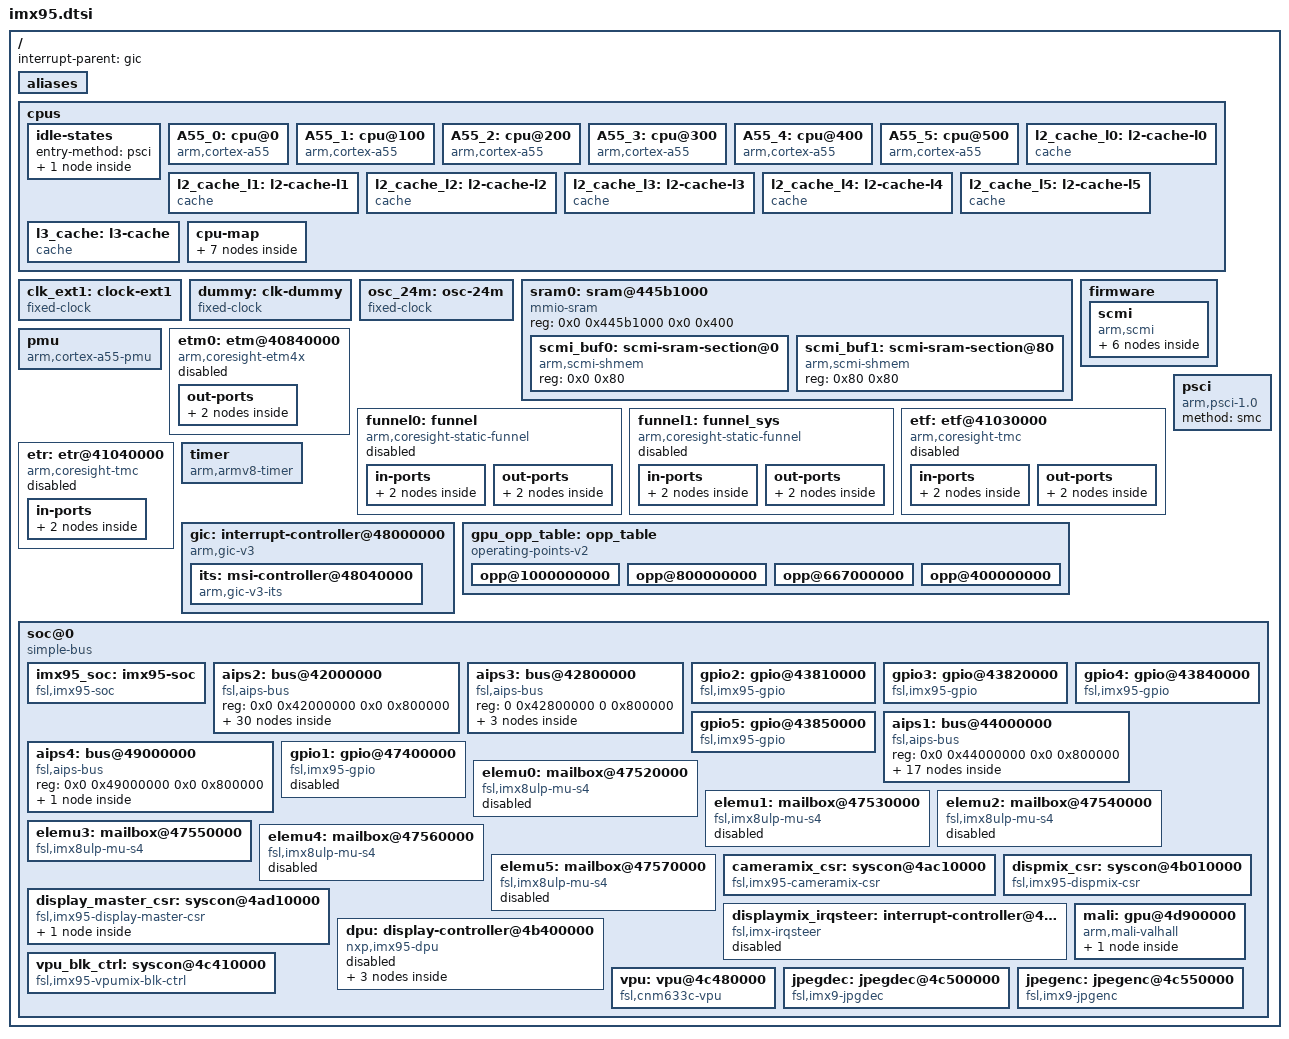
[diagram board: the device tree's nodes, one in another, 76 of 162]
// SPDX-License-Identifier: (GPL-2.0+ OR MIT)
/*
 * Copyright 2023 NXP
 */

#include <dt-bindings/clock/fsl,imx95-clock.h>
#include <dt-bindings/gpio/gpio.h>
#include <dt-bindings/input/input.h>
#include <dt-bindings/interrupt-controller/arm-gic.h>
#include <dt-bindings/power/fsl,imx95-power.h>

#include "imx95-pinfunc.h"

/ {
	interrupt-parent = <&gic>;
	#address-cells = <2>;
	#size-cells = <2>;

	aliases {
		gpio0 = &gpio1;
		gpio1 = &gpio2;
		gpio2 = &gpio3;
		gpio3 = &gpio4;
		gpio4 = &gpio5;
		i2c0 = &lpi2c1;
		i2c1 = &lpi2c2;
		i2c2 = &lpi2c3;
		i2c3 = &lpi2c4;
		i2c4 = &lpi2c5;
		i2c5 = &lpi2c6;
		i2c6 = &lpi2c7;
		i2c7 = &lpi2c8;
		mmc0 = &usdhc1;
		mmc1 = &usdhc2;
		mmc2 = &usdhc3;
		serial0 = &lpuart1;
		serial1 = &lpuart2;
		serial2 = &lpuart3;
		serial3 = &lpuart4;
		serial4 = &lpuart5;
		serial5 = &lpuart6;
		serial6 = &lpuart7;
		serial7 = &lpuart8;
	};

	cpus {
		#address-cells = <1>;
		#size-cells = <0>;

		idle-states {
			entry-method = "psci";

			cpu_pd_wait: cpu-pd-wait {
				compatible = "arm,idle-state";
				arm,psci-suspend-param = <0x0010033>;
				local-timer-stop;
				/*
				entry-latency-us = <10000>;
				exit-latency-us = <7000>;
				min-residency-us = <27000>;
				wakeup-latency-us = <15000>;
				*/
				entry-latency-us = <1000>;
				exit-latency-us = <700>;
				min-residency-us = <2700>;
				wakeup-latency-us = <1500>;
			};
		};

		A55_0: cpu@0 {
			device_type = "cpu";
			compatible = "arm,cortex-a55";
			reg = <0x0>;
			enable-method = "psci";
			#cooling-cells = <2>;
			cpu-idle-states = <&cpu_pd_wait>;
			power-domains = <&scmi_devpd IMX95_PERF_A55>;
			power-domain-names = "perf";
			i-cache-size = <32768>;
			i-cache-line-size = <64>;
			i-cache-sets = <128>;
			d-cache-size = <32768>;
			d-cache-line-size = <64>;
			d-cache-sets = <128>;
			next-level-cache = <&l2_cache_l0>;
		};

		A55_1: cpu@100 {
			device_type = "cpu";
			compatible = "arm,cortex-a55";
			reg = <0x100>;
			enable-method = "psci";
			#cooling-cells = <2>;
			cpu-idle-states = <&cpu_pd_wait>;
			power-domains = <&scmi_devpd IMX95_PERF_A55>;
			power-domain-names = "perf";
			i-cache-size = <32768>;
			i-cache-line-size = <64>;
			i-cache-sets = <128>;
			d-cache-size = <32768>;
			d-cache-line-size = <64>;
			d-cache-sets = <128>;
			next-level-cache = <&l2_cache_l1>;
		};

		A55_2: cpu@200 {
			device_type = "cpu";
			compatible = "arm,cortex-a55";
			reg = <0x200>;
			enable-method = "psci";
			#cooling-cells = <2>;
			cpu-idle-states = <&cpu_pd_wait>;
			power-domains = <&scmi_devpd IMX95_PERF_A55>;
			power-domain-names = "perf";
			i-cache-size = <32768>;
			i-cache-line-size = <64>;
			i-cache-sets = <128>;
			d-cache-size = <32768>;
			d-cache-line-size = <64>;
			d-cache-sets = <128>;
			next-level-cache = <&l2_cache_l2>;
		};

		A55_3: cpu@300 {
			device_type = "cpu";
			compatible = "arm,cortex-a55";
			reg = <0x300>;
			enable-method = "psci";
			#cooling-cells = <2>;
			power-domains = <&scmi_devpd IMX95_PERF_A55>;
			power-domain-names = "perf";
			i-cache-size = <32768>;
			i-cache-line-size = <64>;
			i-cache-sets = <128>;
			d-cache-size = <32768>;
			d-cache-line-size = <64>;
			d-cache-sets = <128>;
			next-level-cache = <&l2_cache_l3>;
		};

		A55_4: cpu@400 {
			device_type = "cpu";
			compatible = "arm,cortex-a55";
			reg = <0x400>;
			power-domains = <&scmi_devpd IMX95_PERF_A55>;
			power-domain-names = "perf";
			enable-method = "psci";
			#cooling-cells = <2>;
			cpu-idle-states = <&cpu_pd_wait>;
			i-cache-size = <32768>;
			i-cache-line-size = <64>;
			i-cache-sets = <128>;
			d-cache-size = <32768>;
			d-cache-line-size = <64>;
			d-cache-sets = <128>;
			next-level-cache = <&l2_cache_l4>;
		};

		A55_5: cpu@500 {
			device_type = "cpu";
			compatible = "arm,cortex-a55";
			reg = <0x500>;
			power-domains = <&scmi_devpd IMX95_PERF_A55>;
			power-domain-names = "perf";
			enable-method = "psci";
			#cooling-cells = <2>;
			cpu-idle-states = <&cpu_pd_wait>;
			i-cache-size = <32768>;
			i-cache-line-size = <64>;
			i-cache-sets = <128>;
			d-cache-size = <32768>;
			d-cache-line-size = <64>;
			d-cache-sets = <128>;
			next-level-cache = <&l2_cache_l5>;
		};

		l2_cache_l0: l2-cache-l0 {
			compatible = "cache";
			cache-size = <65536>;
			cache-line-size = <64>;
			cache-sets = <256>;
			cache-level = <2>;
			cache-unified;
			next-level-cache = <&l3_cache>;
		};

		l2_cache_l1: l2-cache-l1 {
			compatible = "cache";
			cache-size = <65536>;
			cache-line-size = <64>;
			cache-sets = <256>;
			cache-level = <2>;
			cache-unified;
			next-level-cache = <&l3_cache>;
		};

		l2_cache_l2: l2-cache-l2 {
			compatible = "cache";
			cache-size = <65536>;
			cache-line-size = <64>;
			cache-sets = <256>;
			cache-level = <2>;
			cache-unified;
			next-level-cache = <&l3_cache>;
		};

		l2_cache_l3: l2-cache-l3 {
			compatible = "cache";
			cache-size = <65536>;
			cache-line-size = <64>;
			cache-sets = <256>;
			cache-level = <2>;
			cache-unified;
			next-level-cache = <&l3_cache>;
		};

		l2_cache_l4: l2-cache-l4 {
			compatible = "cache";
			cache-size = <65536>;
			cache-line-size = <64>;
			cache-sets = <256>;
			cache-level = <2>;
			cache-unified;
			next-level-cache = <&l3_cache>;
		};

		l2_cache_l5: l2-cache-l5 {
			compatible = "cache";
			cache-size = <65536>;
			cache-line-size = <64>;
			cache-sets = <256>;
			cache-level = <2>;
			cache-unified;
			next-level-cache = <&l3_cache>;
		};

		l3_cache: l3-cache {
			compatible = "cache";
			cache-size = <524288>;
			cache-line-size = <64>;
			cache-sets = <1024>;
			cache-level = <3>;
			cache-unified;
		};

		cpu-map {
			cluster0 {
				core0 {
					cpu = <&A55_0>;
				};

				core1 {
					cpu = <&A55_1>;
				};

				core2 {
					cpu = <&A55_2>;
				};

				core3 {
					cpu = <&A55_3>;
				};

				core4 {
					cpu = <&A55_4>;
				};

				core5 {
					cpu = <&A55_5>;
				};
			};
		};
	};

	clk_ext1: clock-ext1 {
		compatible = "fixed-clock";
		#clock-cells = <0>;
		clock-frequency = <133000000>;
		clock-output-names = "clk_ext1";
	};

	dummy: clk-dummy {
		compatible = "fixed-clock";
		#clock-cells = <0>;
		clock-frequency = <0>;
		clock-output-names = "dummy";
	};

	osc_24m: osc-24m {
		compatible = "fixed-clock";
		#clock-cells = <0>;
		clock-frequency = <24000000>;
		clock-output-names = "osc_24m";
	};

	sram0: sram@445b1000 {
		compatible = "mmio-sram";
		reg = <0x0 0x445b1000 0x0 0x400>;

		#address-cells = <1>;
		#size-cells = <1>;
		ranges = <0x0 0x0 0x445b1000 0x400>;

		scmi_buf0: scmi-sram-section@0 {
			compatible = "arm,scmi-shmem";
			reg = <0x0 0x80>;
		};

		scmi_buf1: scmi-sram-section@80 {
			compatible = "arm,scmi-shmem";
			reg = <0x80 0x80>;
		};
	};

	firmware {
		scmi {
			compatible = "arm,scmi";
			mboxes = <&mu2 5 0>, <&mu2 3 0>, <&mu2 3 1>;
			shmem = <&scmi_buf0>, <&scmi_buf1>;
			#address-cells = <1>;
			#size-cells = <0>;

			scmi_devpd: protocol@11 {
				reg = <0x11>;
				#power-domain-cells = <1>;
			};

			scmi_sys_power: protocol@12 {
				reg = <0x12>;
			};

			scmi_perf: protocol@13 {
				reg = <0x13>;
				#clock-cells = <1>;
				#power-domain-cells = <1>;
			};

			scmi_clk: protocol@14 {
				reg = <0x14>;
				#clock-cells = <1>;
			};

			scmi_iomuxc: protocol@19 {
				reg = <0x19>;
			};

			scmi_bbm: protocol@81 {
				reg = <0x81>;
			};
		};
	};

	pmu {
		compatible = "arm,cortex-a55-pmu";
		interrupts = <GIC_PPI 7 (GIC_CPU_MASK_SIMPLE(6) | IRQ_TYPE_LEVEL_HIGH)>;
	};

	etm0: etm@40840000 {
		compatible = "arm,coresight-etm4x", "arm,primecell";
		reg = <0x0 0x40840000 0x0 0x10000>;
		arm,primecell-periphid = <0xbb95d>;
		cpu = <&A55_0>;
		clocks = <&scmi_clk IMX95_CLK_A55PERIPH>;
		clock-names = "apb_pclk";
		status = "disabled";

		out-ports {
			port {
				etm0_out_port: endpoint {
					remote-endpoint = <&ca_funnel_in_port0>;
				};
			};
		};
	};

	funnel0: funnel {
		/*
		 * non-configurable funnel don't show up on the AMBA
		 * bus.  As such no need to add "arm,primecell".
		 */
		compatible = "arm,coresight-static-funnel";
		status = "disabled";

		in-ports {
			#address-cells = <1>;
			#size-cells = <0>;

			port@0 {
				reg = <0>;
				ca_funnel_in_port0: endpoint {
					remote-endpoint = <&etm0_out_port>;
				};
			};
		};

		out-ports {
			port {
				ca_funnel_out_port0: endpoint {
					remote-endpoint = <&hugo_funnel_in_port0>;
				};
			};
		};
	};

	funnel1: funnel_sys {
		compatible = "arm,coresight-static-funnel";
		status = "disabled";

		in-ports {
			#address-cells = <1>;
			#size-cells = <0>;

			port@0 {
				reg = <0>;
				hugo_funnel_in_port0: endpoint {
					remote-endpoint = <&ca_funnel_out_port0>;
				};
			};
		};

		out-ports {
			port {
				hugo_funnel_out_port0: endpoint {
					remote-endpoint = <&etf_in_port>;
				};
			};
		};
	};

	etf: etf@41030000 {
		compatible = "arm,coresight-tmc", "arm,primecell";
		reg = <0x0 0x41030000 0x0 0x1000>;
		clocks = <&scmi_clk IMX95_CLK_A55PERIPH>;
		clock-names = "apb_pclk";
		status = "disabled";

		in-ports {
			port {
				etf_in_port: endpoint {
					remote-endpoint = <&hugo_funnel_out_port0>;
				};
			};
		};

		out-ports {
			port {
				etf_out_port: endpoint {
					remote-endpoint = <&etr_in_port>;
				};
			};
		};
	};

	etr: etr@41040000 {
		compatible = "arm,coresight-tmc", "arm,primecell";
		reg = <0x0 0x41040000 0x0 0x1000>;
		clocks = <&scmi_clk IMX95_CLK_A55PERIPH>;
		clock-names = "apb_pclk";
		status = "disabled";

		in-ports {
			port {
				etr_in_port: endpoint {
					remote-endpoint = <&etf_out_port>;
				};
			};
		};
	};

	psci {
		compatible = "arm,psci-1.0";
		method = "smc";
	};

	timer {
		compatible = "arm,armv8-timer";
		interrupts = <GIC_PPI 13 (GIC_CPU_MASK_SIMPLE(6) | IRQ_TYPE_LEVEL_LOW)>,
			     <GIC_PPI 14 (GIC_CPU_MASK_SIMPLE(6) | IRQ_TYPE_LEVEL_LOW)>,
			     <GIC_PPI 11 (GIC_CPU_MASK_SIMPLE(6) | IRQ_TYPE_LEVEL_LOW)>,
			     <GIC_PPI 10 (GIC_CPU_MASK_SIMPLE(6) | IRQ_TYPE_LEVEL_LOW)>;
		clock-frequency = <24000000>;
		arm,no-tick-in-suspend;
		interrupt-parent = <&gic>;
	};

	gic: interrupt-controller@48000000 {
		compatible = "arm,gic-v3";
		#address-cells = <2>;
		#size-cells = <2>;
		reg = <0 0x48000000 0 0x10000>,
		      <0 0x48060000 0 0xc0000>;
		#interrupt-cells = <3>;
		interrupt-controller;
		interrupts = <GIC_PPI 9 IRQ_TYPE_LEVEL_HIGH>;
		interrupt-parent = <&gic>;
		dma-noncoherent;

		ranges;

		its: msi-controller@48040000 {
			compatible = "arm,gic-v3-its";
			dma-noncoherent;
			msi-controller;
			reg = <0 0x48040000 0 0x20000>;
		};
	};


	gpu_opp_table: opp_table {
		compatible = "operating-points-v2", "operating-points-v2-mali";

		opp@1000000000 {
			opp-hz = /bits/ 64 <1000000000>;
			opp-hz-real = /bits/ 64 <1000000000>, /bits/ 64 <500000000>;
		};

		opp@800000000 {
			opp-hz = /bits/ 64 <800000000>;
			opp-hz-real = /bits/ 64 <800000000>, /bits/ 64 <500000000>;
		};

		opp@667000000 {
			opp-hz = /bits/ 64 <667000000>;
			opp-hz-real = /bits/ 64 <667000000>, /bits/ 64 <400000000>;
		};

		opp@400000000 {
			opp-hz = /bits/ 64 <400000000>;
			opp-hz-real = /bits/ 64 <400000000>, /bits/ 64 <250000000>;
		};
	};

	soc@0 {
		compatible = "simple-bus";
		#address-cells = <2>;
		#size-cells = <2>;
		ranges = <0x0 0x0 0x0 0x0 0x0 0x80000000>,
			 <0x0 0x28000000 0x0 0x28000000 0x0 0x10000000>;

		imx95_soc: imx95-soc {
			compatible = "fsl,imx95-soc";
		};

		aips2: bus@42000000 {
			compatible = "fsl,aips-bus", "simple-bus";
			reg = <0x0 0x42000000 0x0 0x800000>;
			#address-cells = <1>;
			#size-cells = <1>;
			ranges = <0x42000000 0x0 0x42000000 0x8000000>;

			mu7: mailbox@42430000 {
				compatible = "fsl,imx95-mu", "fsl,imx8ulp-mu";
				reg = <0x42430000 0x10000>;
				interrupts = <GIC_SPI 234 IRQ_TYPE_LEVEL_HIGH>;
				clocks = <&scmi_clk IMX95_CLK_BUSWAKEUP>;
				#mbox-cells = <2>;
				status = "disabled";
			};

			flexcan2: can@425b0000 {
				compatible = "fsl,imx95-flexcan", "fsl,imx93-flexcan";
				reg = <0x425b0000 0x10000>;
				interrupts = <GIC_SPI 38 IRQ_TYPE_LEVEL_HIGH>;
				clocks = <&scmi_clk IMX95_CLK_BUSWAKEUP>,
					 <&scmi_clk IMX95_CLK_CAN2>;
				clock-names = "ipg", "per";
				assigned-clocks = <&scmi_clk IMX95_CLK_CAN2>;
				assigned-clock-parents = <&scmi_clk IMX95_CLK_SYSPLL1_PFD1_DIV2>;
				assigned-clock-rates = <40000000>;
				fsl,clk-source = /bits/ 8 <0>;
				status = "disabled";
			};

			flexcan3: can@42600000 {
				compatible = "fsl,imx95-flexcan", "fsl,imx93-flexcan";
				reg = <0x42600000 0x10000>;
				interrupts = <GIC_SPI 40 IRQ_TYPE_LEVEL_HIGH>;
				clocks = <&scmi_clk IMX95_CLK_BUSWAKEUP>,
					 <&scmi_clk IMX95_CLK_CAN3>;
				clock-names = "ipg", "per";
				assigned-clocks = <&scmi_clk IMX95_CLK_CAN3>;
				assigned-clock-parents = <&scmi_clk IMX95_CLK_SYSPLL1_PFD1_DIV2>;
				assigned-clock-rates = <40000000>;
				fsl,clk-source = /bits/ 8 <0>;
				status = "disabled";
			};

			mu8: mailbox@42730000 {
				compatible = "fsl,imx95-mu", "fsl,imx8ulp-mu";
				reg = <0x42730000 0x10000>;
				interrupts = <GIC_SPI 235 IRQ_TYPE_LEVEL_HIGH>;
				clocks = <&scmi_clk IMX95_CLK_BUSWAKEUP>;
				#mbox-cells = <2>;
				status = "disabled";
			};

			tpm3: pwm@424e0000 {
				compatible = "fsl,imx7ulp-pwm";
				reg = <0x424e0000 0x1000>;
				clocks = <&scmi_clk IMX95_CLK_BUSWAKEUP>;
				#pwm-cells = <3>;
				status = "disabled";
			};

			tpm4: pwm@424f0000 {
				compatible = "fsl,imx7ulp-pwm";
				reg = <0x424f0000 0x1000>;
				clocks = <&scmi_clk IMX95_CLK_TPM4>;
				#pwm-cells = <3>;
				status = "disabled";
			};

			tpm5: pwm@42500000 {
				compatible = "fsl,imx7ulp-pwm";
				reg = <0x42500000 0x1000>;
				clocks = <&scmi_clk IMX95_CLK_TPM5>;
				#pwm-cells = <3>;
				status = "disabled";
			};

			tpm6: pwm@42510000 {
				compatible = "fsl,imx7ulp-pwm";
				reg = <0x42510000 0x1000>;
				clocks = <&scmi_clk IMX95_CLK_TPM6>;
				#pwm-cells = <3>;
				status = "disabled";
			};

			lpi2c3: i2c@42530000 {
				compatible = "fsl,imx95-lpi2c", "fsl,imx7ulp-lpi2c";
				reg = <0x42530000 0x10000>;
				interrupts = <GIC_SPI 58 IRQ_TYPE_LEVEL_HIGH>;
				clocks = <&scmi_clk IMX95_CLK_LPI2C3>,
					 <&scmi_clk IMX95_CLK_BUSWAKEUP>;
				clock-names = "per", "ipg";
				status = "disabled";
			};

			lpi2c4: i2c@42540000 {
				compatible = "fsl,imx95-lpi2c", "fsl,imx7ulp-lpi2c";
				reg = <0x42540000 0x10000>;
				interrupts = <GIC_SPI 59 IRQ_TYPE_LEVEL_HIGH>;
				clocks = <&scmi_clk IMX95_CLK_LPI2C4>,
					 <&scmi_clk IMX95_CLK_BUSWAKEUP>;
				clock-names = "per", "ipg";
				status = "disabled";
			};

			lpspi3: spi@42550000 {
				#address-cells = <1>;
				#size-cells = <0>;
				compatible = "fsl,imx95-spi", "fsl,imx7ulp-spi";
				reg = <0x42550000 0x10000>;
				interrupts = <GIC_SPI 61 IRQ_TYPE_LEVEL_HIGH>;
				clocks = <&scmi_clk IMX95_CLK_LPSPI3>,
					 <&scmi_clk IMX95_CLK_BUSWAKEUP>;
				clock-names = "per", "ipg";
				status = "disabled";
			};

			lpspi4: spi@42560000 {
				#address-cells = <1>;
				#size-cells = <0>;
				compatible = "fsl,imx95-spi", "fsl,imx7ulp-spi";
				reg = <0x42560000 0x10000>;
				interrupts = <GIC_SPI 62 IRQ_TYPE_LEVEL_HIGH>;
				clocks = <&scmi_clk IMX95_CLK_LPSPI4>,
					 <&scmi_clk IMX95_CLK_BUSWAKEUP>;
				clock-names = "per", "ipg";
				status = "disabled";
			};

			lpuart3: serial@42570000 {
				compatible = "fsl,imx95-lpuart", "fsl,imx8ulp-lpuart",
					     "fsl,imx7ulp-lpuart";
				reg = <0x42570000 0x1000>;
				interrupts = <GIC_SPI 64 IRQ_TYPE_LEVEL_HIGH>;
				clocks = <&scmi_clk IMX95_CLK_LPUART3>;
				clock-names = "ipg";
				status = "disabled";
			};

			lpuart4: serial@42580000 {
				compatible = "fsl,imx95-lpuart", "fsl,imx8ulp-lpuart",
					     "fsl,imx7ulp-lpuart";
				reg = <0x42580000 0x1000>;
				interrupts = <GIC_SPI 65 IRQ_TYPE_LEVEL_HIGH>;
				clocks = <&scmi_clk IMX95_CLK_LPUART4>;
				clock-names = "ipg";
				status = "disabled";
			};

			lpuart5: serial@42590000 {
				compatible = "fsl,imx95-lpuart", "fsl,imx8ulp-lpuart",
					     "fsl,imx7ulp-lpuart";
				reg = <0x42590000 0x1000>;
				interrupts = <GIC_SPI 66 IRQ_TYPE_LEVEL_HIGH>;
				clocks = <&scmi_clk IMX95_CLK_LPUART5>;
				clock-names = "ipg";
				status = "disabled";
			};

			lpuart6: serial@425a0000 {
				compatible = "fsl,imx95-lpuart", "fsl,imx8ulp-lpuart",
					     "fsl,imx7ulp-lpuart";
				reg = <0x425a0000 0x1000>;
				interrupts = <GIC_SPI 67 IRQ_TYPE_LEVEL_HIGH>;
				clocks = <&scmi_clk IMX95_CLK_LPUART6>;
				clock-names = "ipg";
				status = "disabled";
			};

			flexio_i2c_master: flexio@425c0000 {
				compatible = "imx,flexio_i2c_master";
				reg = <0x425c0000 0x10000>;
				interrupts = <GIC_SPI 46 IRQ_TYPE_LEVEL_HIGH>;
				clocks = <&scmi_clk IMX95_CLK_BUSWAKEUP>,
					 <&scmi_clk IMX95_CLK_BUSWAKEUP>;
				clock-names = "per", "ipg";
				assigned-clocks = <&scmi_clk IMX95_CLK_BUSWAKEUP>;
				assigned-clock-parents = <&scmi_clk IMX95_CLK_BUSWAKEUP>;
				assigned-clock-rates = <24000000>;
				status = "disabled";
			};

			flexspi1: spi@425e0000 {
				#address-cells = <1>;
				#size-cells = <0>;
				compatible = "nxp,imx95-fspi", "nxp,imx8mm-fspi";
				reg = <0x425e0000 0x10000>, <0x28000000 0x8000000>;
				reg-names = "fspi_base", "fspi_mmap";
				interrupts = <GIC_SPI 48 IRQ_TYPE_LEVEL_HIGH>;
				clocks = <&scmi_clk IMX95_CLK_FLEXSPI1>,
					 <&scmi_clk IMX95_CLK_FLEXSPI1>;
				clock-names = "fspi", "fspi_en";
				assigned-clocks = <&scmi_clk IMX95_CLK_FLEXSPI1>;
				assigned-clock-parents = <&scmi_clk IMX95_CLK_SYSPLL1_PFD1>;
				assigned-clock-rates = <200000000>;
				status = "disabled";
			};

			lpuart7: serial@42690000 {
				compatible = "fsl,imx95-lpuart", "fsl,imx8ulp-lpuart",
					     "fsl,imx7ulp-lpuart";
				reg = <0x42690000 0x1000>;
				interrupts = <GIC_SPI 68 IRQ_TYPE_LEVEL_HIGH>;
				clocks = <&scmi_clk IMX95_CLK_LPUART7>;
				clock-names = "ipg";
				status = "disabled";
			};

			lpuart8: serial@426a0000 {
				compatible = "fsl,imx95-lpuart", "fsl,imx8ulp-lpuart",
					     "fsl,imx7ulp-lpuart";
				reg = <0x426a0000 0x1000>;
				interrupts = <GIC_SPI 69 IRQ_TYPE_LEVEL_HIGH>;
				clocks = <&scmi_clk IMX95_CLK_LPUART8>;
				clock-names = "ipg";
				status = "disabled";
			};

			lpi2c5: i2c@426b0000 {
				compatible = "fsl,imx95-lpi2c", "fsl,imx7ulp-lpi2c";
				reg = <0x426b0000 0x10000>;
				interrupts = <GIC_SPI 181 IRQ_TYPE_LEVEL_HIGH>;
				clocks = <&scmi_clk IMX95_CLK_LPI2C5>,
					 <&scmi_clk IMX95_CLK_BUSWAKEUP>;
				clock-names = "per", "ipg";
				status = "disabled";
			};

			lpi2c6: i2c@426c0000 {
				compatible = "fsl,imx95-lpi2c", "fsl,imx7ulp-lpi2c";
				reg = <0x426c0000 0x10000>;
				interrupts = <GIC_SPI 182 IRQ_TYPE_LEVEL_HIGH>;
				clocks = <&scmi_clk IMX95_CLK_LPI2C6>,
					 <&scmi_clk IMX95_CLK_BUSWAKEUP>;
				clock-names = "per", "ipg";
				status = "disabled";
			};

			lpi2c7: i2c@426d0000 {
				compatible = "fsl,imx95-lpi2c", "fsl,imx7ulp-lpi2c";
				reg = <0x426d0000 0x10000>;
				interrupts = <GIC_SPI 183 IRQ_TYPE_LEVEL_HIGH>;
				clocks = <&scmi_clk IMX95_CLK_LPI2C7>,
					 <&scmi_clk IMX95_CLK_BUSWAKEUP>;
				clock-names = "per", "ipg";
				status = "disabled";
			};

			lpi2c8: i2c@426e0000 {
				compatible = "fsl,imx95-lpi2c", "fsl,imx7ulp-lpi2c";
				reg = <0x426e0000 0x10000>;
				interrupts = <GIC_SPI 184 IRQ_TYPE_LEVEL_HIGH>;
				clocks = <&scmi_clk IMX95_CLK_LPI2C8>,
					 <&scmi_clk IMX95_CLK_BUSWAKEUP>;
				clock-names = "per", "ipg";
				status = "disabled";
			};

			lpspi5: spi@426f0000 {
				#address-cells = <1>;
				#size-cells = <0>;
				compatible = "fsl,imx95-spi", "fsl,imx7ulp-spi";
				reg = <0x426f0000 0x10000>;
				interrupts = <GIC_SPI 177 IRQ_TYPE_LEVEL_HIGH>;
				clocks = <&scmi_clk IMX95_CLK_LPSPI5>,
					 <&scmi_clk IMX95_CLK_BUSWAKEUP>;
				clock-names = "per", "ipg";
				status = "disabled";
			};

			lpspi6: spi@42700000 {
				#address-cells = <1>;
				#size-cells = <0>;
				compatible = "fsl,imx95-spi", "fsl,imx7ulp-spi";
				reg = <0x42700000 0x10000>;
				interrupts = <GIC_SPI 178 IRQ_TYPE_LEVEL_HIGH>;
				clocks = <&scmi_clk IMX95_CLK_LPSPI6>,
					 <&scmi_clk IMX95_CLK_BUSWAKEUP>;
				clock-names = "per", "ipg";
				status = "disabled";
			};

			lpspi7: spi@42710000 {
				#address-cells = <1>;
				#size-cells = <0>;
				compatible = "fsl,imx95-spi", "fsl,imx7ulp-spi";
				reg = <0x42710000 0x10000>;
				interrupts = <GIC_SPI 179 IRQ_TYPE_LEVEL_HIGH>;
				clocks = <&scmi_clk IMX95_CLK_LPSPI7>,
					 <&scmi_clk IMX95_CLK_BUSWAKEUP>;
				clock-names = "per", "ipg";
				status = "disabled";
			};

			lpspi8: spi@42720000 {
				#address-cells = <1>;
				#size-cells = <0>;
				compatible = "fsl,imx95-spi", "fsl,imx7ulp-spi";
				reg = <0x42720000 0x10000>;
				interrupts = <GIC_SPI 180 IRQ_TYPE_LEVEL_HIGH>;
				clocks = <&scmi_clk IMX95_CLK_LPSPI8>,
					 <&scmi_clk IMX95_CLK_BUSWAKEUP>;
				clock-names = "per", "ipg";
				status = "disabled";
			};

			flexcan4: can@427c0000 {
				compatible = "fsl,imx95-flexcan", "fsl,imx93-flexcan";
				reg = <0x427c0000 0x10000>;
				interrupts = <GIC_SPI 42 IRQ_TYPE_LEVEL_HIGH>;
				clocks = <&scmi_clk IMX95_CLK_BUSWAKEUP>,
					 <&scmi_clk IMX95_CLK_CAN4>;
				clock-names = "ipg", "per";
				assigned-clocks = <&scmi_clk IMX95_CLK_CAN4>;
				assigned-clock-parents = <&scmi_clk IMX95_CLK_SYSPLL1_PFD1_DIV2>;
				assigned-clock-rates = <40000000>;
				fsl,clk-source = /bits/ 8 <0>;
				status = "disabled";
			};

			flexcan5: can@427d0000 {
				compatible = "fsl,imx95-flexcan", "fsl,imx93-flexcan";
				reg = <0x427d0000 0x10000>;
				interrupts = <GIC_SPI 44 IRQ_TYPE_LEVEL_HIGH>;
				clocks = <&scmi_clk IMX95_CLK_BUSWAKEUP>,
					 <&scmi_clk IMX95_CLK_CAN5>;
				clock-names = "ipg", "per";
				assigned-clocks = <&scmi_clk IMX95_CLK_CAN5>;
				assigned-clock-parents = <&scmi_clk IMX95_CLK_SYSPLL1_PFD1_DIV2>;
				assigned-clock-rates = <40000000>;
				fsl,clk-source = /bits/ 8 <0>;
				status = "disabled";
			};
		};

		aips3: bus@42800000 {
			compatible = "fsl,aips-bus", "simple-bus";
			reg = <0 0x42800000 0 0x800000>;
			#address-cells = <1>;
			#size-cells = <1>;
			ranges = <0x42800000 0x0 0x42800000 0x800000>;

			usdhc1: mmc@42850000 {
				compatible = "fsl,imx95-usdhc", "fsl,imx8mm-usdhc";
				reg = <0x42850000 0x10000>;
				interrupts = <GIC_SPI 86 IRQ_TYPE_LEVEL_HIGH>;
				clocks = <&scmi_clk IMX95_CLK_BUSWAKEUP>,
					 <&scmi_clk IMX95_CLK_WAKEUPAXI>,
					 <&scmi_clk IMX95_CLK_USDHC1>;
				clock-names = "ipg", "ahb", "per";
				assigned-clocks = <&scmi_clk IMX95_CLK_USDHC1>;
				assigned-clock-parents = <&scmi_clk IMX95_CLK_SYSPLL1_PFD1>;
				assigned-clock-rates = <400000000>;
				bus-width = <8>;
				fsl,tuning-start-tap = <1>;
				fsl,tuning-step= <2>;
				status = "disabled";
			};

			usdhc2: mmc@42860000 {
				compatible = "fsl,imx95-usdhc", "fsl,imx8mm-usdhc";
				reg = <0x42860000 0x10000>;
				interrupts = <GIC_SPI 87 IRQ_TYPE_LEVEL_HIGH>;
				clocks = <&scmi_clk IMX95_CLK_BUSWAKEUP>,
					 <&scmi_clk IMX95_CLK_WAKEUPAXI>,
					 <&scmi_clk IMX95_CLK_USDHC2>;
				clock-names = "ipg", "ahb", "per";
				assigned-clocks = <&scmi_clk IMX95_CLK_USDHC2>;
				assigned-clock-parents = <&scmi_clk IMX95_CLK_SYSPLL1_PFD1>;
				assigned-clock-rates = <200000000>;
				bus-width = <4>;
				fsl,tuning-start-tap = <1>;
				fsl,tuning-step= <2>;
				status = "disabled";
			};

			usdhc3: mmc@428b0000 {
				compatible = "fsl,imx95-usdhc", "fsl,imx8mm-usdhc";
				reg = <0x428b0000 0x10000>;
				interrupts = <GIC_SPI 191 IRQ_TYPE_LEVEL_HIGH>;
				clocks = <&scmi_clk IMX95_CLK_BUSWAKEUP>,
					 <&scmi_clk IMX95_CLK_WAKEUPAXI>,
					 <&scmi_clk IMX95_CLK_USDHC3>;
				clock-names = "ipg", "ahb", "per";
				bus-width = <4>;
				fsl,tuning-start-tap = <1>;
				fsl,tuning-step= <2>;
				status = "disabled";
			};
		};

		gpio2: gpio@43810000 {
			compatible = "fsl,imx95-gpio", "fsl,imx8ulp-gpio";
			reg = <0x0 0x43810000 0x0 0x1000>;
			gpio-controller;
			#gpio-cells = <2>;
			interrupts = <GIC_SPI 49 IRQ_TYPE_LEVEL_HIGH>,
				     <GIC_SPI 50 IRQ_TYPE_LEVEL_HIGH>;
			interrupt-controller;
			#interrupt-cells = <2>;
			clocks = <&scmi_clk IMX95_CLK_BUSWAKEUP>,
				 <&scmi_clk IMX95_CLK_BUSWAKEUP>;
			clock-names = "gpio", "port";
			gpio-ranges = <&scmi_iomuxc 0 4 32>;
		};

		gpio3: gpio@43820000 {
			compatible = "fsl,imx95-gpio", "fsl,imx8ulp-gpio";
			reg = <0x0 0x43820000 0x0 0x1000>;
			gpio-controller;
			#gpio-cells = <2>;
			interrupts = <GIC_SPI 51 IRQ_TYPE_LEVEL_HIGH>,
				     <GIC_SPI 52 IRQ_TYPE_LEVEL_HIGH>;
			interrupt-controller;
			#interrupt-cells = <2>;
			clocks = <&scmi_clk IMX95_CLK_BUSWAKEUP>,
				 <&scmi_clk IMX95_CLK_BUSWAKEUP>;
			clock-names = "gpio", "port";
			gpio-ranges = <&scmi_iomuxc 0 104 8>, <&scmi_iomuxc 8 74 18>,
				      <&scmi_iomuxc 26 42 2>, <&scmi_iomuxc 28 0 4>;
		};

		gpio4: gpio@43840000 {
			compatible = "fsl,imx95-gpio", "fsl,imx8ulp-gpio";
			reg = <0x0 0x43840000 0x0 0x1000>;
			gpio-controller;
			#gpio-cells = <2>;
			interrupts = <GIC_SPI 53 IRQ_TYPE_LEVEL_HIGH>,
				     <GIC_SPI 54 IRQ_TYPE_LEVEL_HIGH>;
			interrupt-controller;
			#interrupt-cells = <2>;
			clocks = <&scmi_clk IMX95_CLK_BUSWAKEUP>,
				 <&scmi_clk IMX95_CLK_BUSWAKEUP>;
			clock-names = "gpio", "port";
			gpio-ranges = <&scmi_iomuxc 0 46 28>, <&scmi_iomuxc 28 44 2>;
		};

		gpio5: gpio@43850000 {
			compatible = "fsl,imx95-gpio", "fsl,imx8ulp-gpio";
			reg = <0x0 0x43850000 0x0 0x1000>;
			gpio-controller;
			#gpio-cells = <2>;
			interrupts = <GIC_SPI 55 IRQ_TYPE_LEVEL_HIGH>,
				     <GIC_SPI 56 IRQ_TYPE_LEVEL_HIGH>;
			interrupt-controller;
			#interrupt-cells = <2>;
			clocks = <&scmi_clk IMX95_CLK_BUSWAKEUP>,
				 <&scmi_clk IMX95_CLK_BUSWAKEUP>;
			clock-names = "gpio", "port";
			gpio-ranges = <&scmi_iomuxc 0 92 12>, <&scmi_iomuxc 12 36 6>;
		};

		aips1: bus@44000000 {
			compatible = "fsl,aips-bus", "simple-bus";
			reg = <0x0 0x44000000 0x0 0x800000>;
			#address-cells = <1>;
			#size-cells = <1>;
			ranges = <0x44000000 0x0 0x44000000 0x800000>;

			edma1: dma-controller@44000000 {
				compatible = "fsl,imx93-edma";
				reg = <0x44000000 0x10000>,
				      <0x44010000 0x10000>, <0x44020000 0x10000>,
				      <0x44030000 0x10000>, <0x44040000 0x10000>,
				      <0x44050000 0x10000>, <0x44060000 0x10000>,
				      <0x44070000 0x10000>, <0x44080000 0x10000>,
				      <0x44090000 0x10000>, <0x440a0000 0x10000>,
				      <0x440b0000 0x10000>, <0x440c0000 0x10000>,
				      <0x440d0000 0x10000>, <0x440e0000 0x10000>,
				      <0x440f0000 0x10000>, <0x44100000 0x10000>,
				      <0x44110000 0x10000>, <0x44120000 0x10000>,
				      <0x44130000 0x10000>, <0x44140000 0x10000>,
				      <0x44150000 0x10000>, <0x44160000 0x10000>,
				      <0x44170000 0x10000>, <0x44180000 0x10000>,
				      <0x44190000 0x10000>, <0x441a0000 0x10000>,
				      <0x441b0000 0x10000>, <0x441c0000 0x10000>,
				      <0x441d0000 0x10000>, <0x441e0000 0x10000>,
				      <0x441f0000 0x10000>;
				#dma-cells = <3>;
				dma-channels = <31>;
				interrupts = <GIC_SPI 96 IRQ_TYPE_LEVEL_HIGH>,
					     <GIC_SPI 97 IRQ_TYPE_LEVEL_HIGH>,
					     <GIC_SPI 98 IRQ_TYPE_LEVEL_HIGH>,
					     <GIC_SPI 99 IRQ_TYPE_LEVEL_HIGH>,
					     <GIC_SPI 100 IRQ_TYPE_LEVEL_HIGH>,
					     <GIC_SPI 101 IRQ_TYPE_LEVEL_HIGH>,
					     <GIC_SPI 102 IRQ_TYPE_LEVEL_HIGH>,
					     <GIC_SPI 103 IRQ_TYPE_LEVEL_HIGH>,
					     <GIC_SPI 104 IRQ_TYPE_LEVEL_HIGH>,
					     <GIC_SPI 105 IRQ_TYPE_LEVEL_HIGH>,
					     <GIC_SPI 106 IRQ_TYPE_LEVEL_HIGH>,
					     <GIC_SPI 107 IRQ_TYPE_LEVEL_HIGH>,
					     <GIC_SPI 108 IRQ_TYPE_LEVEL_HIGH>,
					     <GIC_SPI 109 IRQ_TYPE_LEVEL_HIGH>,
					     <GIC_SPI 110 IRQ_TYPE_LEVEL_HIGH>,
					     <GIC_SPI 111 IRQ_TYPE_LEVEL_HIGH>,
					     <GIC_SPI 112 IRQ_TYPE_LEVEL_HIGH>,
					     <GIC_SPI 113 IRQ_TYPE_LEVEL_HIGH>,
					     <GIC_SPI 114 IRQ_TYPE_LEVEL_HIGH>,
					     <GIC_SPI 115 IRQ_TYPE_LEVEL_HIGH>,
					     <GIC_SPI 116 IRQ_TYPE_LEVEL_HIGH>,
					     <GIC_SPI 117 IRQ_TYPE_LEVEL_HIGH>,
					     <GIC_SPI 118 IRQ_TYPE_LEVEL_HIGH>,
					     <GIC_SPI 119 IRQ_TYPE_LEVEL_HIGH>,
					     <GIC_SPI 120 IRQ_TYPE_LEVEL_HIGH>,
					     <GIC_SPI 121 IRQ_TYPE_LEVEL_HIGH>,
					     <GIC_SPI 122 IRQ_TYPE_LEVEL_HIGH>,
					     <GIC_SPI 123 IRQ_TYPE_LEVEL_HIGH>,
					     <GIC_SPI 124 IRQ_TYPE_LEVEL_HIGH>,
					     <GIC_SPI 125 IRQ_TYPE_LEVEL_HIGH>,
					     <GIC_SPI 126 IRQ_TYPE_LEVEL_HIGH>,
					     <GIC_SPI 95 IRQ_TYPE_LEVEL_HIGH>;
				interrupt-names = "edma1-chan0-tx", "edma1-chan1-tx",
						  "edma1-chan2-tx", "edma1-chan3-tx",
						  "edma1-chan4-tx", "edma1-chan5-tx",
						  "edma1-chan6-tx", "edma1-chan7-tx",
						  "edma1-chan8-tx", "edma1-chan9-tx",
						  "edma1-chan10-tx", "edma1-chan11-tx",
						  "edma1-chan12-tx", "edma1-chan13-tx",
						  "edma1-chan14-tx", "edma1-chan15-tx",
						  "edma1-chan16-tx", "edma1-chan17-tx",
						  "edma1-chan18-tx", "edma1-chan19-tx",
						  "edma1-chan20-tx", "edma1-chan21-tx",
						  "edma1-chan22-tx", "edma1-chan23-tx",
						  "edma1-chan24-tx", "edma1-chan25-tx",
						  "edma1-chan26-tx", "edma1-chan27-tx",
						  "edma1-chan28-tx", "edma1-chan29-tx",
						  "edma1-chan30-tx", "edma1-err";
				clocks = <&scmi_clk IMX95_CLK_BUSAON>;
				clock-names = "edma";
				status = "disabled";
			};

			mu1: mailbox@44220000 {
				compatible = "fsl,imx95-mu", "fsl,imx8ulp-mu";
				reg = <0x44220000 0x10000>;
				interrupts = <GIC_SPI 224 IRQ_TYPE_LEVEL_HIGH>;
				clocks = <&scmi_clk IMX95_CLK_BUSAON>;
				#mbox-cells = <2>;
				status = "disabled";
			};

			flexcan1: can@443a0000 {
				compatible = "fsl,imx95-flexcan", "fsl,imx93-flexcan";
				reg = <0x443a0000 0x10000>;
				interrupts = <GIC_SPI 8 IRQ_TYPE_LEVEL_HIGH>;
				clocks = <&scmi_clk IMX95_CLK_BUSAON>,
					 <&scmi_clk IMX95_CLK_CAN1>;
				clock-names = "ipg", "per";
				assigned-clocks = <&scmi_clk IMX95_CLK_CAN1>;
				assigned-clock-parents = <&scmi_clk IMX95_CLK_SYSPLL1_PFD1_DIV2>;
				assigned-clock-rates = <40000000>;
				fsl,clk-source = /bits/ 8 <0>;
				status = "disabled";
			};

			mu2: mailbox@445b0000 {
				compatible = "fsl,imx95-mu", "fsl,imx8ulp-mu";
				reg = <0x445b0000 0x1000>;
				interrupts = <GIC_SPI 226 IRQ_TYPE_LEVEL_HIGH>;
				/*clocks = <&scmi_clk IMX95_CLK_BUSAON>;*/
				#mbox-cells = <2>;
			};

			mu3: mailbox@445d0000 {
				compatible = "fsl,imx95-mu", "fsl,imx8ulp-mu";
				reg = <0x445d0000 0x10000>;
				interrupts = <GIC_SPI 228 IRQ_TYPE_LEVEL_HIGH>;
				clocks = <&scmi_clk IMX95_CLK_BUSAON>;
				#mbox-cells = <2>;
				status = "disabled";
			};

			mu4: mailbox@445f0000 {
				compatible = "fsl,imx95-mu", "fsl,imx8ulp-mu";
				reg = <0x445f0000 0x10000>;
				interrupts = <GIC_SPI 230 IRQ_TYPE_LEVEL_HIGH>;
				clocks = <&scmi_clk IMX95_CLK_BUSAON>;
				#mbox-cells = <2>;
				status = "disabled";
			};

			mu6: mailbox@44630000 {
				compatible = "fsl,imx95-mu", "fsl,imx8ulp-mu";
				reg = <0x44630000 0x10000>;
				interrupts = <GIC_SPI 206 IRQ_TYPE_LEVEL_HIGH>;
				clocks = <&scmi_clk IMX95_CLK_BUSAON>;
				#mbox-cells = <2>;
				status = "disabled";
			};

			system_counter: timer@44290000 {
				compatible = "nxp,imx95-sysctr-timer", "nxp,sysctr-timer";
				reg = <0x44290000 0x30000>;
				interrupts = <GIC_SPI 72 IRQ_TYPE_LEVEL_HIGH>;
				clocks = <&osc_24m>;
				clock-names = "per";
				nxp,no-divider;
			};

			tpm1: pwm@44310000 {
				compatible = "fsl,imx7ulp-pwm";
				reg = <0x44310000 0x1000>;
				clocks = <&scmi_clk IMX95_CLK_BUSAON>;
				#pwm-cells = <3>;
				status = "disabled";
			};

			tpm2: pwm@44320000 {
				compatible = "fsl,imx7ulp-pwm";
				reg = <0x44320000 0x1000>;
				clocks = <&scmi_clk IMX95_CLK_TPM2>;
				assigned-clocks = <&scmi_clk IMX95_CLK_TPM2>;
				assigned-clock-parents = <&scmi_clk IMX95_CLK_24M>;
				assigned-clock-rates = <24000000>;
				#pwm-cells = <3>;
				status = "disabled";
			};

			lpi2c1: i2c@44340000 {
				compatible = "fsl,imx95-lpi2c", "fsl,imx7ulp-lpi2c";
				reg = <0x44340000 0x10000>;
				interrupts = <GIC_SPI 13 IRQ_TYPE_LEVEL_HIGH>;
				clocks = <&scmi_clk IMX95_CLK_LPI2C1>,
					 <&scmi_clk IMX95_CLK_BUSAON>;
				clock-names = "per", "ipg";
				status = "disabled";
			};

			lpi2c2: i2c@44350000 {
				compatible = "fsl,imx95-lpi2c", "fsl,imx7ulp-lpi2c";
				reg = <0x44350000 0x10000>;
				interrupts = <GIC_SPI 14 IRQ_TYPE_LEVEL_HIGH>;
				clocks = <&scmi_clk IMX95_CLK_LPI2C2>,
					 <&scmi_clk IMX95_CLK_BUSAON>;
				clock-names = "per", "ipg";
				status = "disabled";
			};

			lpspi1: spi@44360000 {
				#address-cells = <1>;
				#size-cells = <0>;
				compatible = "fsl,imx95-spi", "fsl,imx7ulp-spi";
				reg = <0x44360000 0x10000>;
				interrupts = <GIC_SPI 16 IRQ_TYPE_LEVEL_HIGH>;
				clocks = <&scmi_clk IMX95_CLK_LPSPI1>,
					 <&scmi_clk IMX95_CLK_BUSAON>;
				clock-names = "per", "ipg";
				status = "disabled";
			};

			lpspi2: spi@44370000 {
				#address-cells = <1>;
				#size-cells = <0>;
				compatible = "fsl,imx95-spi", "fsl,imx7ulp-spi";
				reg = <0x44370000 0x10000>;
				interrupts = <GIC_SPI 17 IRQ_TYPE_LEVEL_HIGH>;
				clocks = <&scmi_clk IMX95_CLK_LPSPI2>,
					 <&scmi_clk IMX95_CLK_BUSAON>;
				clock-names = "per", "ipg";
				status = "disabled";
			};

			lpuart1: serial@44380000 {
				compatible = "fsl,imx95-lpuart", "fsl,imx8ulp-lpuart",
					     "fsl,imx7ulp-lpuart";
				reg = <0x44380000 0x1000>;
				interrupts = <GIC_SPI 19 IRQ_TYPE_LEVEL_HIGH>;
				clocks = <&scmi_clk IMX95_CLK_LPUART1>;
				clock-names = "ipg";
				status = "disabled";
			};

			lpuart2: serial@44390000 {
				compatible = "fsl,imx95-lpuart", "fsl,imx8ulp-lpuart",
					     "fsl,imx7ulp-lpuart";
				reg = <0x44390000 0x1000>;
				interrupts = <GIC_SPI 20 IRQ_TYPE_LEVEL_HIGH>;
				clocks = <&scmi_clk IMX95_CLK_LPUART2>;
				clock-names = "ipg";
				status = "disabled";
			};

			adc1: adc@44530000 {
				compatible = "nxp,imx93-adc";
				reg = <0x44530000 0x10000>;
				interrupts = <GIC_SPI 199 IRQ_TYPE_LEVEL_HIGH>,
						<GIC_SPI 200 IRQ_TYPE_LEVEL_HIGH>,
						<GIC_SPI 201 IRQ_TYPE_LEVEL_HIGH>;
				clocks = <&scmi_clk IMX95_CLK_ADC>;
				clock-names = "ipg";
				status = "disabled";
			};

		};

		aips4: bus@49000000 {
			compatible = "fsl,aips-bus", "simple-bus";
			reg = <0x0 0x49000000 0x0 0x800000>;
			#address-cells = <1>;
			#size-cells = <1>;
			ranges = <0x49000000 0x0 0x49000000 0x800000>;

			smmu: iommu@490d0000 {
				compatible = "arm,smmu-v3";
				reg = <0x490d0000 0x100000>;
				interrupts = <GIC_SPI 325 IRQ_TYPE_EDGE_RISING>,
					     <GIC_SPI 328 IRQ_TYPE_EDGE_RISING>,
					     <GIC_SPI 334 IRQ_TYPE_EDGE_RISING>,
					     <GIC_SPI 326 IRQ_TYPE_EDGE_RISING>;
				interrupt-names = "eventq", "gerror", "priq", "cmdq-sync";
				#iommu-cells = <1>;
				status = "disabled";
			};
		};

		gpio1: gpio@47400000 {
			compatible = "fsl,imx95-gpio", "fsl,imx8ulp-gpio";
			reg = <0x0 0x47400000 0x0 0x1000>;
			gpio-controller;
			#gpio-cells = <2>;
			interrupts = <GIC_SPI 10 IRQ_TYPE_LEVEL_HIGH>,
				     <GIC_SPI 11 IRQ_TYPE_LEVEL_HIGH>;
			interrupt-controller;
			#interrupt-cells = <2>;
			clocks = <&scmi_clk IMX95_CLK_M33>,
				 <&scmi_clk IMX95_CLK_M33>;
			clock-names = "gpio", "port";
			gpio-ranges = <&scmi_iomuxc 0 112 16>;
			status = "disabled";
		};

		elemu0: mailbox@47520000 {
			compatible = "fsl,imx8ulp-mu-s4";
			reg = <0x0 0x47520000 0x0 0x10000>;
			interrupts = <GIC_SPI 21 IRQ_TYPE_LEVEL_HIGH>;
			#mbox-cells = <2>;
			status = "disabled";
		};

		elemu1: mailbox@47530000 {
			compatible = "fsl,imx8ulp-mu-s4";
			reg = <0x0 0x47530000 0x0 0x10000>;
			interrupts = <GIC_SPI 22 IRQ_TYPE_LEVEL_HIGH>;
			#mbox-cells = <2>;
			status = "disabled";
		};

		elemu2: mailbox@47540000 {
			compatible = "fsl,imx8ulp-mu-s4";
			reg = <0x0 0x47540000 0x0 0x10000>;
			interrupts = <GIC_SPI 23 IRQ_TYPE_LEVEL_HIGH>;
			#mbox-cells = <2>;
			status = "disabled";
		};

		elemu3: mailbox@47550000 {
			compatible = "fsl,imx8ulp-mu-s4";
			reg = <0x0 0x47550000 0x0 0x10000>;
			interrupts = <GIC_SPI 24 IRQ_TYPE_LEVEL_HIGH>;
			#mbox-cells = <2>;
		};

		elemu4: mailbox@47560000 {
			compatible = "fsl,imx8ulp-mu-s4";
			reg = <0x0 0x47560000 0x0 0x10000>;
			interrupts = <GIC_SPI 25 IRQ_TYPE_LEVEL_HIGH>;
			#mbox-cells = <2>;
			status = "disabled";
		};

		elemu5: mailbox@47570000 {
			compatible = "fsl,imx8ulp-mu-s4";
			reg = <0x0 0x47570000 0x0 0x10000>;
			interrupts = <GIC_SPI 26 IRQ_TYPE_LEVEL_HIGH>;
			#mbox-cells = <2>;
			status = "disabled";
		};

		cameramix_csr: syscon@4ac10000 {
			compatible = "fsl,imx95-cameramix-csr", "syscon";
			#address-cells = <1>;
			#size-cells = <1>;
			reg = <0x0 0x4ac10000 0x0 0x10000>;
			#clock-cells = <1>;
			clocks = <&scmi_clk IMX95_CLK_CAMAPB>;
			power-domains = <&scmi_devpd IMX95_PD_CAMERA>;
			assigned-clocks = <&scmi_clk IMX95_CLK_CAMAXI>,
					  <&scmi_clk IMX95_CLK_CAMAPB>;
			assigned-clock-parents = <&scmi_clk IMX95_CLK_SYSPLL1_PFD1>,
						 <&scmi_clk IMX95_CLK_SYSPLL1_PFD1_DIV2>;
			assigned-clock-rates = <800000000>, <133333333>;
		};

		display_master_csr: syscon@4ad10000 {
			compatible = "fsl,imx95-display-master-csr", "syscon";
			reg = <0x0 0x4ad10000 0x0 0x10000>;
			#clock-cells = <1>;
			clocks = <&scmi_clk IMX95_CLK_CAMAPB>;
			power-domains = <&scmi_devpd IMX95_PD_CAMERA>;

			mux: mux-controller {
				compatible = "mmio-mux";
				#mux-control-cells = <1>;
				mux-reg-masks = <0x4 0x00000001>; /* Pixel_link_sel */
			};
		};

		dispmix_csr: syscon@4b010000 {
			compatible = "fsl,imx95-dispmix-csr", "syscon";
			#address-cells = <1>;
			#size-cells = <1>;
			reg = <0x0 0x4b010000 0x0 0x10000>;
			#clock-cells = <1>;
			clocks = <&scmi_clk IMX95_CLK_DISPAPB>;
			power-domains = <&scmi_devpd IMX95_PD_DISPLAY>;
			assigned-clocks = <&scmi_clk IMX95_CLK_DISPAXI>,
					  <&scmi_clk IMX95_CLK_DISPOCRAM>,
					  <&scmi_clk IMX95_CLK_DISPAPB>;
			assigned-clock-parents = <&scmi_clk IMX95_CLK_SYSPLL1_PFD1>,
						 <&scmi_clk IMX95_CLK_SYSPLL1_PFD1>,
						 <&scmi_clk IMX95_CLK_SYSPLL1_PFD1_DIV2>;
			assigned-clock-rates = <400000000>, <400000000>, <133333333>;
		};

		displaymix_irqsteer: interrupt-controller@4b0b0000 {
			compatible = "fsl,imx-irqsteer";
			reg = <0x0 0x4b0b0000 0x0 0x1000>;
			interrupts = <GIC_SPI 214 IRQ_TYPE_LEVEL_HIGH>,
				     <GIC_SPI 215 IRQ_TYPE_LEVEL_HIGH>,
				     <GIC_SPI 216 IRQ_TYPE_LEVEL_HIGH>,
				     <GIC_SPI 217 IRQ_TYPE_LEVEL_HIGH>,
				     <GIC_SPI 218 IRQ_TYPE_LEVEL_HIGH>,
				     <GIC_SPI 303 IRQ_TYPE_LEVEL_HIGH>,	/* reserved */
				     <GIC_SPI 303 IRQ_TYPE_LEVEL_HIGH>,	/* reserved */
				     <GIC_SPI 219 IRQ_TYPE_LEVEL_HIGH>;
			power-domains = <&scmi_devpd IMX95_PD_DISPLAY>;
			clocks = <&scmi_clk IMX95_CLK_DISPAPB>;
			clock-names = "ipg";
			fsl,channel = <0>;
			fsl,num-irqs = <512>;
			interrupt-controller;
			#interrupt-cells = <1>;
			status = "disabled";
		};

		dpu: display-controller@4b400000 {
			compatible = "nxp,imx95-dpu";
			reg = <0x0 0x4b400000 0x0 0x400000>;
			interrupt-parent = <&displaymix_irqsteer>;
			interrupts = <448>, <449>, <450>,  <64>,
				      <65>,  <66>,  <67>,  <68>,
				      <69>, <192>, <193>, <194>,
				     <195>, <196>, <197>,  <70>,
				      <71>,  <72>,  <73>,  <74>,
				      <75>,  <76>,  <77>,  <78>,
				      <79>,  <80>,  <81>,  <82>,
				      <83>,  <84>,  <85>,  <86>,
				      <87>,  <88>,  <89>,  <90>,
				      <91>,  <92>, <198>, <199>,
				     <200>, <201>, <202>, <203>,
				     <204>, <205>, <206>, <207>,
				     <208>, <209>, <210>, <211>,
				     <212>, <451>,   <1>,   <2>,
				       <3>,   <4>,  <93>,  <94>,
				      <95>,  <96>,  <97>,  <98>,
				      <99>, <100>, <101>, <102>,
				     <103>, <104>, <105>, <106>,
				     <213>, <214>, <215>, <216>,
				     <217>, <218>, <219>, <220>,
				     <221>, <222>, <223>, <224>,
				     <225>, <226>;
			interrupt-names = "store9_shdload",
					  "store9_framecomplete",
					  "store9_seqcomplete",
					  "extdst0_shdload",
					  "extdst0_framecomplete",
					  "extdst0_seqcomplete",
					  "extdst4_shdload",
					  "extdst4_framecomplete",
					  "extdst4_seqcomplete",
					  "extdst1_shdload",
					  "extdst1_framecomplete",
					  "extdst1_seqcomplete",
					  "extdst5_shdload",
					  "extdst5_framecomplete",
					  "extdst5_seqcomplete",
					  "domainblend0_shdload",
					  "domainblend0_framecomplete",
					  "domainblend0_seqcomplete",
					  "disengcfg_shdload0",
					  "disengcfg_framecomplete0",
					  "disengcfg_seqcomplete0",
					  "framegen0_int0",
					  "framegen0_int1",
					  "framegen0_int2",
					  "framegen0_int3",
					  "sig0_shdload",
					  "sig0_valid",
					  "sig0_error",
					  "sig0_cluster_error",
					  "sig0_cluster_match",
					  "sig2_shdload",
					  "sig2_valid",
					  "sig2_error",
					  "sig2_cluster_error",
					  "sig2_cluster_match",
					  "idhash0_shdload",
					  "idhash0_valid",
					  "idhash0_window_error",
					  "domainblend1_shdload",
					  "domainblend1_framecomplete",
					  "domainblend1_seqcomplete",
					  "disengcfg_shdload1",
					  "disengcfg_framecomplete1",
					  "disengcfg_seqcomplete1",
					  "framegen1_int0",
					  "framegen1_int1",
					  "framegen1_int2",
					  "framegen1_int3",
					  "sig1_shdload",
					  "sig1_valid",
					  "sig1_error",
					  "sig1_cluster_error",
					  "sig1_cluster_match",
					  "cmdseq_error",
					  "comctrl_sw0",
					  "comctrl_sw1",
					  "comctrl_sw2",
					  "comctrl_sw3",
					  "framegen0_primsync_on",
					  "framegen0_primsync_off",
					  "framegen0_overflow0_on",
					  "framegen0_overflow0_off",
					  "framegen0_underrun0_on",
					  "framegen0_underrun0_off",
					  "framegen0_threshold0_rise",
					  "framegen0_threshold0_fail",
					  "framegen0_overflow1_on",
					  "framegen0_overflow1_off",
					  "framegen0_underrun1_on",
					  "framegen0_underrun1_off",
					  "framegen0_threshold1_rise",
					  "framegen0_threshold1_fail",
					  "framegen1_primsync_on",
					  "framegen1_primsync_off",
					  "framegen1_overflow0_on",
					  "framegen1_overflow0_off",
					  "framegen1_underrun0_on",
					  "framegen1_underrun0_off",
					  "framegen1_threshold0_rise",
					  "framegen1_threshold0_fail",
					  "framegen1_overflow1_on",
					  "framegen1_overflow1_off",
					  "framegen1_underrun1_on",
					  "framegen1_underrun1_off",
					  "framegen1_threshold1_rise",
					  "framegen1_threshold1_fail";
			clocks = <&scmi_clk IMX95_CLK_DISP1PIX>,
				 <&scmi_clk IMX95_CLK_DISPAPB>,
				 <&scmi_clk IMX95_CLK_DISPAXI>,
				 <&scmi_clk IMX95_CLK_DISPOCRAM>,
				 <&scmi_clk IMX95_CLK_LDBPLL>;
			clock-names = "pix", "apb", "axi", "ocram", "ldb";
			power-domains = <&scmi_devpd IMX95_PD_DISPLAY>;
			nxp,blk-ctrl = <&dispmix_csr>;
			status = "disabled";

			ports {
				#address-cells = <1>;
				#size-cells = <0>;

				port@0 {
					reg = <0>;
				};

				port@1 {
					reg = <1>;
				};
			};
		};

		vpu_blk_ctrl: syscon@4c410000 {
			compatible = "fsl,imx95-vpumix-blk-ctrl", "syscon";
			reg = <0x0 0x4c410000 0x0 0x10000>;
			#clock-cells = <1>;
			clocks = <&scmi_clk IMX95_CLK_VPUAPB>;
			power-domains = <&scmi_devpd IMX95_PD_VPU>;
			assigned-clocks = <&scmi_clk IMX95_CLK_VPUAPB>,
					  <&scmi_clk IMX95_CLK_VPU>,
					  <&scmi_clk IMX95_CLK_VPUJPEG>;
			assigned-clock-parents = <&scmi_clk IMX95_CLK_SYSPLL1_PFD1_DIV2>,
						 <&scmi_clk IMX95_CLK_SYSPLL1_PFD2>,
						 <&scmi_clk IMX95_CLK_SYSPLL1_PFD0>;
			assigned-clock-rates = <133333333>, <667000000>, <500000000>;
		};

		mali: gpu@4d900000 {
			compatible = "arm,mali-valhall";
			reg = <0 0x4d900000 0 0x700000>, <0 0x4d810000 0 0x10000>;
			interrupts = <GIC_SPI 288 IRQ_TYPE_LEVEL_HIGH>,
				     <GIC_SPI 289 IRQ_TYPE_LEVEL_HIGH>,
				     <GIC_SPI 290 IRQ_TYPE_LEVEL_HIGH>;
			interrupt-names = "GPU", "JOB", "MMU";
			clocks = <&scmi_clk IMX95_CLK_GPU>, <&scmi_clk IMX95_CLK_GPUAPB>;
			clock-names = "gpu", "gpu_apb";
			power-domains = <&scmi_devpd IMX95_PD_GPU>;
			operating-points-v2 = <&gpu_opp_table>;
			#cooling-cells = <2>;
			power_model {
			    compatible = "arm,mali-simple-power-model";
			    static-coefficient = <2427750>;
			    dynamic-coefficient = <4687>;
			    ts = <20000 2000 (-20) 2>;
			    thermal-zone = "gpu";
			};
		};

		vpu: vpu@4c480000 {
			compatible = "fsl,cnm633c-vpu";
			reg = <0x0 0x4c480000 0x0 0x10000>, <0x0 0x4c4c0000 0x0 0x10000>;
			interrupts = <GIC_SPI 299 IRQ_TYPE_LEVEL_HIGH>;
			clocks = <&scmi_clk IMX95_CLK_VPU>,
				 <&vpu_blk_ctrl IMX95_CLK_VPUBLK_WAVE>;
			power-domains = <&scmi_devpd IMX95_PD_VPU>;
		};

		jpegdec: jpegdec@4c500000 {
			compatible = "fsl,imx9-jpgdec";
			reg = <0x0 0x4C500000 0x0 0x00050000>;
			interrupts = <GIC_SPI 295 IRQ_TYPE_LEVEL_HIGH>,
				     <GIC_SPI 296 IRQ_TYPE_LEVEL_HIGH>,
				     <GIC_SPI 297 IRQ_TYPE_LEVEL_HIGH>,
				     <GIC_SPI 298 IRQ_TYPE_LEVEL_HIGH>;
			slot = <0>;
			clocks = <&scmi_clk IMX95_CLK_VPU>,
				 <&scmi_clk IMX95_CLK_VPUJPEG>,
				 <&vpu_blk_ctrl IMX95_CLK_VPUBLK_JPEG_DEC>;
			power-domains = <&scmi_devpd IMX95_PD_VPU>;
			power-domain-names = "pd_dec";
		};

		jpegenc: jpegenc@4c550000 {
			compatible = "fsl,imx9-jpgenc";
			reg = <0x0 0x4C550000 0x0 0x00050000>;
			interrupts = <GIC_SPI 291 IRQ_TYPE_LEVEL_HIGH>,
				     <GIC_SPI 292 IRQ_TYPE_LEVEL_HIGH>,
				     <GIC_SPI 293 IRQ_TYPE_LEVEL_HIGH>,
				     <GIC_SPI 294 IRQ_TYPE_LEVEL_HIGH>;
			slot = <0>;
			clocks = <&scmi_clk IMX95_CLK_VPU>,
				 <&scmi_clk IMX95_CLK_VPUJPEG>,
				 <&vpu_blk_ctrl IMX95_CLK_VPUBLK_JPEG_ENC>;
			power-domains = <&scmi_devpd IMX95_PD_VPU>;
			power-domain-names = "pd_enc";
		};
	};
};
